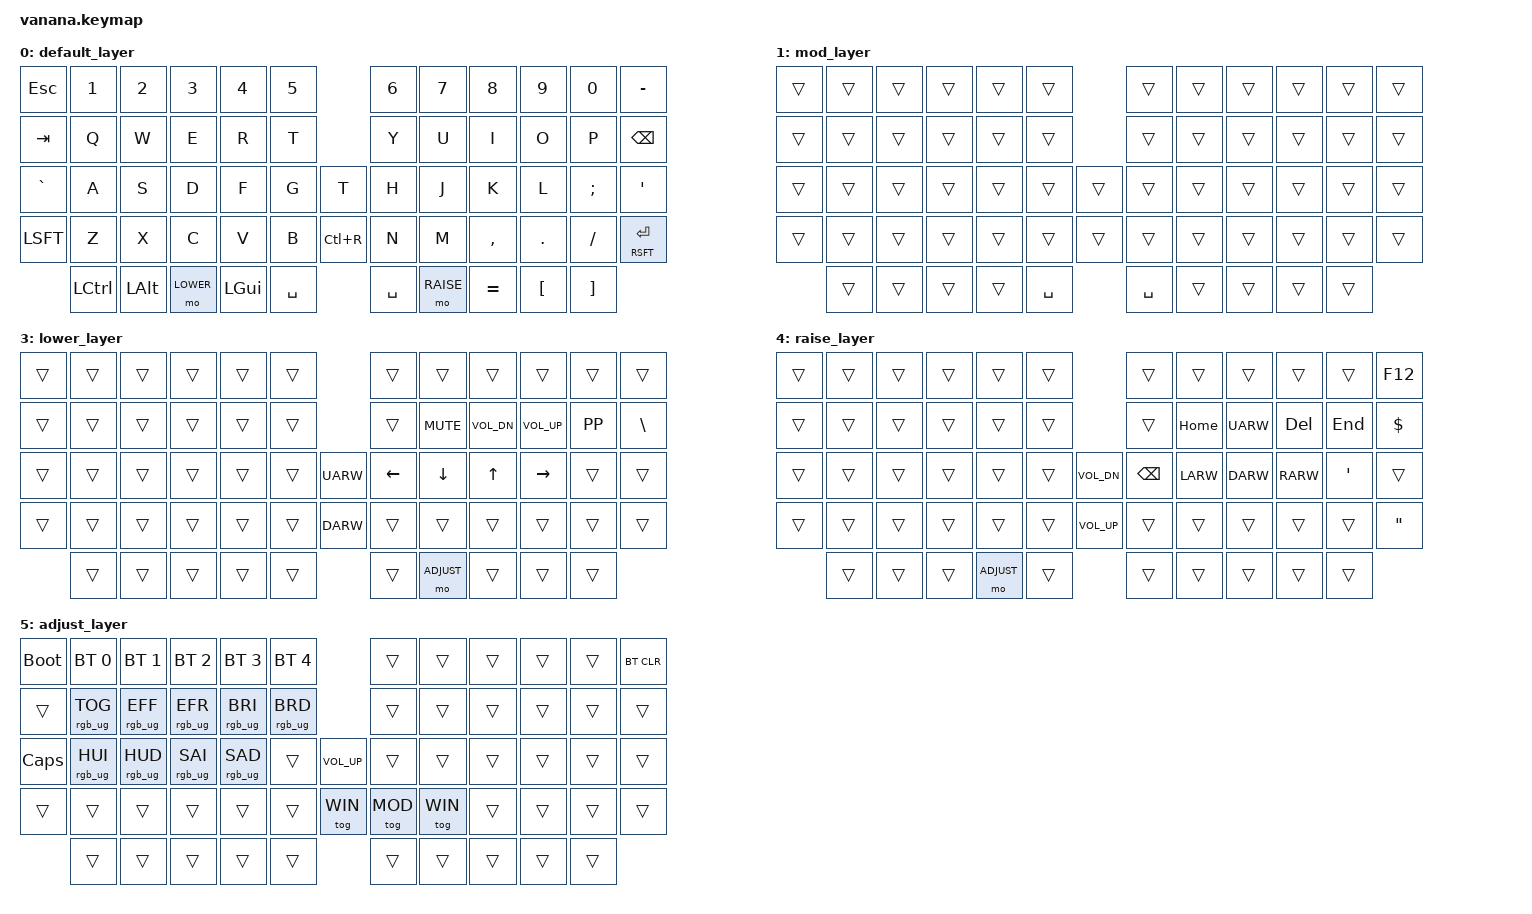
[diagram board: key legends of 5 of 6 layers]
/*
 * Copyright (c) 2020 dELLIKEEb
 *
 * SPDX-License-Identifier: MIT
 * Edited by tgray
 */

#include <behaviors.dtsi>
#include <dt-bindings/zmk/keys.h>
#include <dt-bindings/zmk/bt.h>
#include <dt-bindings/zmk/rgb.h>

// custom keycode defs for easier access
#define DEFAULT 0
#define MOD     1
#define WIN     2
#define LOWER   3
#define RAISE   4
#define ADJUST  5

// / {
//     behaviors {
//         hm: homerow_mods {
//             compatible = "zmk,behavior-hold-tap";
//             label = "homerow mods";
//             #binding-cells = <2>;
//             tapping_term_ms = <225>;
//             flavor = "tap-preferred";
//             bindings = <&kp>, <&kp>;
//         };
//     };
// };

// BASE
// -------------------------------------------               -------------------------------------------
// | ESC  |   1  |   2  |   3  |   4  |   5  |               |   6  |   7  |   8  |   9  |   0  |   -  |
// -------------------------------------------               -------------------------------------------
// | Tab  |   Q  |   W  |   E  |   R  |   T  |               |   Y  |   U  |   I  |   O  |   P  | Bksp |
// -------------------------------------------   ---------  --------------------------------------------
// |  `   |   A  |   S  |   D  |   F  |   G  |   | Right |   |   H  |   J  |   K  |   L  |   ;  |   '  |
// -------------------------------------------   ---------   -------------------------------------------
// | Shift|   Z  |   X  |   C  |   V  |   B  |   | LEFT  |   |   N  |   M  |   ,  |   .  |   /  | Enter|
// -------------------------------------------   ---------   -------------------------------------------
//        | Ctrl | Alt  | Lower| GUI  |Space |               |Space |Raise |Alt   |   [  |   ]  |
//        ------------------------------------               ------------------------------------
// 

/ {
    keymap {
        compatible = "zmk,keymap";

        default_layer {
            bindings = <
                &kp ESC    &kp N1      &kp N2      &kp N3      &kp N4    &kp N5                    &kp N6      &kp N7      &kp N8      &kp N9      &kp N0      &kp MINUS
                &kp TAB     &kp Q       &kp W       &kp E       &kp R     &kp T                     &kp Y       &kp U       &kp I       &kp O       &kp P       &kp BKSP
                &kp GRAVE   &kp A       &kp S       &kp D       &kp F     &kp G         &kp T       &kp H       &kp J       &kp K       &kp L       &kp SCLN    &kp SQT
                &kp LSFT    &kp Z       &kp X       &kp C       &kp V     &kp B         &kp LC(R)   &kp N       &kp M       &kp CMMA    &kp DOT     &kp FSLH    &mt RSFT RET
                            &kp LCTRL   &kp LALT    &mo LOWER   &kp LGUI  &kp SPC                   &kp SPC     &mo RAISE   &kp EQUAL   &kp LBKT    &kp RBKT
            >;
            sensor-bindings = <&inc_dec_kp LA(RIGHT) LA(LEFT) &inc_dec_kp LA(RIGHT) LA(LEFT)>;
        };

        mod_layer {
            bindings = <
                &trans      &trans      &trans      &trans      &trans      &trans                  &trans      &trans      &trans      &trans      &trans      &trans  
                &trans      &trans      &trans      &trans      &trans      &trans                  &trans      &trans      &trans      &trans      &trans      &trans
                &trans      &trans      &trans      &trans      &trans      &trans      &trans      &trans      &trans      &trans      &trans      &trans      &trans
                &trans      &trans      &trans      &trans      &trans      &trans      &trans      &trans      &trans      &trans      &trans      &trans      &trans 
                            &trans      &trans      &trans      &trans      &kp SPC                 &kp SPC     &trans      &trans      &trans      &trans
            >;
            sensor-bindings = <&inc_dec_kp C_VOL_DN C_VOL_UP &inc_dec_kp LEFT RIGHT>;
        };

        win_layer {
            bindings = <
                &trans      &trans      &trans      &trans      &trans      &trans                  &trans      &trans      &trans      &trans      &trans      &trans  
                &trans      &trans      &trans      &trans      &trans      &trans                  &trans      &trans      &trans      &trans      &trans      &trans
                &trans      &trans      &trans      &trans      &trans      &trans      &trans      &trans      &trans      &trans      &trans      &trans      &trans      &trans      &trans      &trans      &trans      &trans      &trans      &trans
                &trans      &trans      &trans      &trans      &trans      &trans      &trans      &trans      &trans      &trans      &trans      &trans      &trans 
                            &trans      &trans      &trans      &trans      &trans                  &trans      &trans      &trans      &trans      &trans
            >;
            sensor-bindings = <&inc_dec_kp LEFT RIGHT &inc_dec_kp LEFT RIGHT>;
        };

        lower_layer {
            bindings = <
                &trans      &trans      &trans      &trans      &trans      &trans                  &trans      &trans      &trans       &trans       &trans      &trans  
                &trans      &trans      &trans      &trans      &trans      &trans                  &trans      &kp C_MUTE  &kp C_VOL_DN &kp C_VOL_UP &kp K_PP    &kp BSLH
                &trans      &trans      &trans      &trans      &trans      &trans      &kp UARW    &kp LEFT    &kp DOWN    &kp UP       &kp RIGHT    &trans      &trans
                &trans      &trans      &trans      &trans      &trans      &trans      &kp DARW    &trans      &trans      &trans       &trans       &trans      &trans
                            &trans      &trans      &trans      &trans      &trans                  &trans      &mo ADJUST  &trans       &trans       &trans
            >;
            sensor-bindings = <&inc_dec_kp C_VOL_UP C_VOL_DN &inc_dec_kp C_VOL_DN C_VOL_UP>;
        };

        raise_layer {
            bindings = <
                &trans      &trans      &trans      &trans      &trans      &trans                      &trans      &trans      &trans      &trans      &trans      &kp F12  
                &trans      &trans      &trans      &trans      &trans      &trans                      &trans      &kp HOME    &kp UARW    &kp DEL     &kp END     &kp DOLLAR
                &trans      &trans      &trans      &trans      &trans      &trans      &kp C_VOL_DN    &kp BSPC    &kp LARW    &kp DARW    &kp RARW    &kp APOS    &trans 
                &trans      &trans      &trans      &trans      &trans      &trans      &kp C_VOL_UP    &trans      &trans      &trans      &trans      &trans      &kp DQT 
                            &trans      &trans      &trans      &mo ADJUST  &trans                      &trans      &trans      &trans      &trans      &trans
            >;
            
        };
        
        adjust_layer {
            bindings = <
                &bootloader &bt BT_SEL 0    &bt BT_SEL 1    &bt BT_SEL 2    &bt BT_SEL 3    &bt BT_SEL 4                    &trans      &trans      &trans      &trans      &trans      &bt BT_CLR        
                &trans      &rgb_ug RGB_TOG &rgb_ug RGB_EFF &rgb_ug RGB_EFR &rgb_ug RGB_BRI &rgb_ug RGB_BRD                 &trans      &trans      &trans      &trans      &trans      &trans
                &kp CAPS    &rgb_ug RGB_HUI &rgb_ug RGB_HUD &rgb_ug RGB_SAI &rgb_ug RGB_SAD &trans          &kp C_VOL_UP    &trans      &trans      &trans      &trans      &trans      &trans  
                &trans      &trans          &trans          &trans          &trans          &trans          &tog WIN        &tog MOD    &tog WIN    &trans      &trans      &trans      &trans  
                            &trans          &trans          &trans          &trans          &trans                          &trans      &trans      &trans      &trans      &trans
            >;
        };

    };
};
